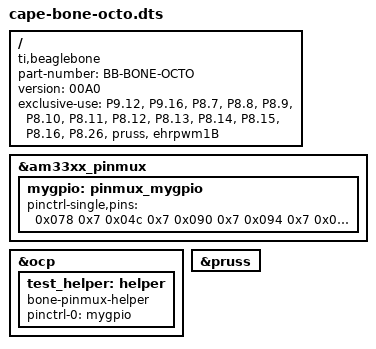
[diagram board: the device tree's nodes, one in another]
/*
* pru dts file BB-BONE-PRU-00A0.dts
*

*/
/dts-v1/;
/plugin/;

/ {
  compatible = "ti,beaglebone", "ti,beaglebone-black";

  /* identification */
  part-number = "BB-BONE-OCTO";
  version = "00A0";

  exclusive-use =
	"P9.12", "P9.16",

	"P8.7", "P8.8", "P8.9", "P8.10", "P8.11", "P8.12", "P8.13",
	"P8.14", "P8.15", "P8.16",

	"P8.26", 

	"pruss",
	"ehrpwm1B";

  fragment@0 {
    target = <&am33xx_pinmux>;
    __overlay__ {
      mygpio: pinmux_mygpio {
        pinctrl-single,pins = <
		// p9.11-18
		0x078 0x7
		0x04c 0x7 // P9.16 could be PWM for output enable

		// p8.7-19
		0x090 0x7
		0x094 0x7
		0x09c 0x7
		0x098 0x7
		0x034 0x7
		0x030 0x7
		0x024 0x7
		0x028 0x7
		0x03c 0x7
		0x038 0x7

		// p8.26-46
		0x07c 0x7
        >;
      };
    };
  };

  fragment@1 {
    target = <&ocp>;
    __overlay__ {
      test_helper: helper {
        compatible = "bone-pinmux-helper";
        pinctrl-names = "default";
        pinctrl-0 = <&mygpio>;
        status = "okay";
      };
    };
  };

  fragment@2{
    target = <&pruss>;
    __overlay__ {
      status = "okay";
    };
  };

/*
  // import of am335x_pwm-00A0.dts
  // but pru can't write to pwm?

	fragment@3 {
		target = <&epwmss0>;
		__overlay__ {
			status = "okay";
		};
	};

	fragment@4 {
		target = <&ehrpwm0>;
		__overlay__ {
			status = "okay";
		};
	};

	fragment@5 {
		target = <&ecap0>;
		__overlay__ {
			status = "okay";
		};
	};

	fragment@6 {
		target = <&epwmss1>;
		__overlay__ {
			status = "okay";
		};
	};

	fragment@7 {
		target = <&ehrpwm1>;
		__overlay__ {
			status = "okay";
		};
	};

	fragment@8 {
		target = <&epwmss2>;
		__overlay__ {
			status = "okay";
		};
	};

	fragment@9 {
		target = <&ehrpwm2>;
		__overlay__ {
			status = "okay";
		};
	};

	fragment@10 {
		target = <&ecap2>;
		__overlay__ {
			status = "okay";
		};
	};
*/
};
